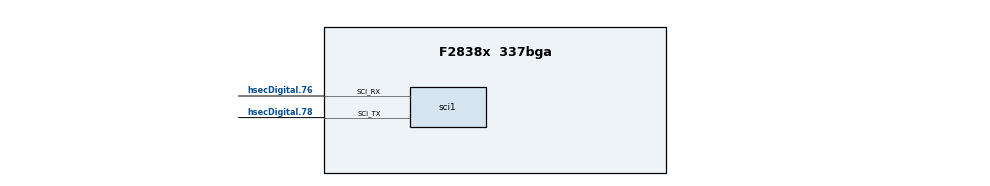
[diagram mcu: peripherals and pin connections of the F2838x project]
/**
 * @cliArgs --board "/boards/TMDSCNCD28388D" --device "F2838x" --part "F2838x_337bga" --package "337bga" --context "CPU1" --product "C2000WARE@26.01.00.00"
 * @versions {"tool":"1.27.1+4634"}
 */

/**
 * Import the modules used in this configuration.
 */
const adc            = scripting.addModule("/driverlib/adc.js", {}, false);
const adc1           = adc.addInstance();
const device_support = scripting.addModule("/driverlib/device_support.js");
const epwm           = scripting.addModule("/driverlib/epwm.js", {}, false);
const epwm1          = epwm.addInstance();
const epwm2          = epwm.addInstance();
const epwm3          = epwm.addInstance();
const memcfg         = scripting.addModule("/driverlib/memcfg.js");
const sci            = scripting.addModule("/driverlib/sci.js", {}, false);
const sci1           = sci.addInstance();
const sysctl         = scripting.addModule("/driverlib/sysctl.js");
const CMD            = scripting.addModule("/utilities/cmd_tool/cmd_syscfg/source/CMD");
const CMD1           = CMD.addInstance();
const CMD2           = CMD.addInstance();

/**
 * Write custom configuration values to the imported modules.
 */
adc1.$name              = "myADC0";
adc1.adcClockPrescaler  = "ADC_CLK_DIV_4_0";
adc1.interruptPulseMode = "ADC_PULSE_END_OF_CONV";
adc1.enabledSOCs        = ["ADC_SOC_NUMBER0"];
adc1.enabledInts        = ["ADC_INT_NUMBER1"];
adc1.soc0Trigger        = "ADC_TRIGGER_EPWM1_SOCA";
adc1.soc0SampleWindow   = 15;
adc1.enableInterrupt1   = true;
adc1.useInterrupts      = false;

epwm1.$name                                                      = "myEPWM0";
epwm1.$hardware                                                  = system.deviceData.board.components.PWM_LOC1;
epwm1.epwmTimebase_counterMode                                   = "EPWM_COUNTER_MODE_UP_DOWN";
epwm1.epwmTimebase_period                                        = 5000;
epwm1.epwmTimebase_hsClockDiv                                    = "EPWM_HSCLOCK_DIVIDER_1";
epwm1.epwmTimebase_syncOutPulseMode                              = ["EPWM_SYNC_OUT_PULSE_ON_CNTR_ZERO"];
epwm1.epwmActionQualifier_EPWM_AQ_OUTPUT_A_ON_TIMEBASE_UP_CMPA   = "EPWM_AQ_OUTPUT_HIGH";
epwm1.epwmActionQualifier_EPWM_AQ_OUTPUT_A_ON_TIMEBASE_DOWN_CMPA = "EPWM_AQ_OUTPUT_LOW";
epwm1.epwmDeadband_enableRED                                     = true;
epwm1.epwmDeadband_delayRED                                      = 25;
epwm1.epwmDeadband_enableFED                                     = true;
epwm1.epwmDeadband_delayFED                                      = 25;
epwm1.epwmDeadband_polarityFED                                   = "EPWM_DB_POLARITY_ACTIVE_LOW";
epwm1.epwmEventTrigger_enableInterrupt                           = true;
epwm1.epwmEventTrigger_EPWM_SOC_A_triggerEnable                  = true;
epwm1.epwmEventTrigger_interruptSource                           = "EPWM_INT_TBCTR_ZERO";
epwm1.epwmEventTrigger_interruptEventCount                       = "1";
epwm1.epwmEventTrigger_EPWM_SOC_A_triggerSource                  = "EPWM_SOC_TBCTR_PERIOD";
epwm1.epwmEventTrigger_EPWM_SOC_A_triggerEventPrescalar          = "1";

epwm2.$name                                                      = "myEPWM1";
epwm2.$hardware                                                  = system.deviceData.board.components.PWM_LOC2;
epwm2.epwmTimebase_counterMode                                   = "EPWM_COUNTER_MODE_UP_DOWN";
epwm2.epwmTimebase_period                                        = 5000;
epwm2.epwmTimebase_hsClockDiv                                    = "EPWM_HSCLOCK_DIVIDER_1";
epwm2.epwmTimebase_phaseEnable                                   = true;
epwm2.epwmActionQualifier_EPWM_AQ_OUTPUT_A_ON_TIMEBASE_UP_CMPA   = "EPWM_AQ_OUTPUT_HIGH";
epwm2.epwmActionQualifier_EPWM_AQ_OUTPUT_A_ON_TIMEBASE_DOWN_CMPA = "EPWM_AQ_OUTPUT_LOW";
epwm2.epwmDeadband_enableRED                                     = true;
epwm2.epwmDeadband_delayRED                                      = 25;
epwm2.epwmDeadband_enableFED                                     = true;
epwm2.epwmDeadband_delayFED                                      = 25;
epwm2.epwmDeadband_polarityFED                                   = "EPWM_DB_POLARITY_ACTIVE_LOW";
epwm2.epwmTimebase_counterModeAfterSync                          = "EPWM_COUNT_MODE_UP_AFTER_SYNC";

epwm3.$name                                                      = "myEPWM2";
epwm3.$hardware                                                  = system.deviceData.board.components.PWM_LOC3;
epwm3.epwmTimebase_counterMode                                   = "EPWM_COUNTER_MODE_UP_DOWN";
epwm3.epwmTimebase_period                                        = 5000;
epwm3.epwmTimebase_hsClockDiv                                    = "EPWM_HSCLOCK_DIVIDER_1";
epwm3.epwmTimebase_phaseEnable                                   = true;
epwm3.epwmActionQualifier_EPWM_AQ_OUTPUT_A_ON_TIMEBASE_UP_CMPA   = "EPWM_AQ_OUTPUT_HIGH";
epwm3.epwmActionQualifier_EPWM_AQ_OUTPUT_A_ON_TIMEBASE_DOWN_CMPA = "EPWM_AQ_OUTPUT_LOW";
epwm3.epwmDeadband_enableRED                                     = true;
epwm3.epwmDeadband_delayRED                                      = 25;
epwm3.epwmDeadband_enableFED                                     = true;
epwm3.epwmDeadband_delayFED                                      = 25;
epwm3.epwmDeadband_polarityFED                                   = "EPWM_DB_POLARITY_ACTIVE_LOW";
epwm3.epwmTimebase_counterModeAfterSync                          = "EPWM_COUNT_MODE_UP_AFTER_SYNC";

sci1.$name                 = "mySCI0";
sci1.useFifo               = false;
sci1.useInterrupts         = false;
sci1.sci.sci_rxPin.$assign = "hsecDigital.76";
sci1.sci.sci_txPin.$assign = "hsecDigital.78";
sci1.rxQual.$name          = "myGPIOQUAL0";
sci1.txQual.$name          = "myGPIOQUAL1";

CMD1.$name                    = "generic_ram_lnk";
CMD1.sectionMemory_ramfunc    = ["RAMM0"];
CMD1.sectionMemory_cinit      = ["RAMM0"];
CMD1.sectionMemory_stack      = ["RAMM1"];
CMD1.sectionMemory_init_array = ["RAMM0"];
CMD1.sectionMemory_bss        = ["RAMLS5"];
CMD1.sectionMemory_const      = ["RAMLS5"];
CMD1.sectionMemory_data       = ["RAMGS0","RAMGS1"];
CMD1.sectionMemory_switch     = ["RAMM0"];
CMD1.sectionMemory_sysmem     = ["RAMLS5"];
CMD1.sectionMemory_text       = ["RAMGS2","RAMGS3","RAMLS0","RAMLS1","RAMLS2","RAMLS3","RAMLS4"];

CMD2.$name                                = "generic_flash_lnk";
CMD2.sectionAlignEnable_ramfunc           = true;
CMD2.sectionAlignEnable_text              = true;
CMD2.sectionAlignEnable_binit             = true;
CMD2.sectionAlignEnable_cinit             = true;
CMD2.sectionAlignEnable_switch            = true;
CMD2.sectionAlignEnable_init_array        = true;
CMD2.sectionAlignEnable_const             = true;
CMD2.sectionAlignEnable_ovly              = true;
CMD2.sectionMemory_codestart              = "0x080000";
CMD2.sectionMemory_stack                  = ["RAMM1"];
CMD2.sectionMemory_bss                    = ["RAMLS5"];
CMD2.sectionMemory_sysmem                 = ["RAMLS5"];
CMD2.sectionMemory_ramfunc                = ["FLASH3"];
CMD2.sectionMemory_text                   = ["FLASH1","FLASH2","FLASH3","FLASH4"];
CMD2.sectionMemory_binit                  = ["FLASH4"];
CMD2.sectionMemory_cinit                  = ["FLASH4"];
CMD2.sectionMemory_switch                 = ["FLASH1"];
CMD2.sectionMemory_init_array             = ["FLASH1"];
CMD2.sectionMemory_const                  = ["FLASH5"];
CMD2.sectionMemory_ovly                   = ["FLASH6"];
CMD2.sectionRunFromDifferentAddr_ramfunc  = true;
CMD2.sectionRun_ramfunc                   = ["RAMLS0"];
CMD2.sectionBinit_ramfunc                 = false;
CMD2.sectionMemory_data                   = ["RAMLS7"];
CMD2.sectionMemory_cla1Prog               = ["FLASH3"];
CMD2.sectionRunFromDifferentAddr_cla1Prog = true;
CMD2.sectionAlignEnable_cla1Prog          = true;

/**
 * Pinmux solution for unlocked pins/peripherals. This ensures that minor changes to the automatic solver in a future
 * version of the tool will not impact the pinmux you originally saw.  These lines can be completely deleted in order to
 * re-solve from scratch.
 */
epwm1.epwm.$suggestSolution           = "EPWM1";
epwm1.epwm.epwm_aPin.$suggestSolution = "hsecDigital.49";
epwm1.epwm.epwm_bPin.$suggestSolution = "hsecDigital.51";
epwm2.epwm.$suggestSolution           = "EPWM2";
epwm2.epwm.epwm_aPin.$suggestSolution = "hsecDigital.53";
epwm2.epwm.epwm_bPin.$suggestSolution = "hsecDigital.55";
epwm3.epwm.$suggestSolution           = "EPWM3";
epwm3.epwm.epwm_aPin.$suggestSolution = "hsecDigital.50";
epwm3.epwm.epwm_bPin.$suggestSolution = "hsecDigital.52";
sci1.sci.$suggestSolution             = "SCIA";
